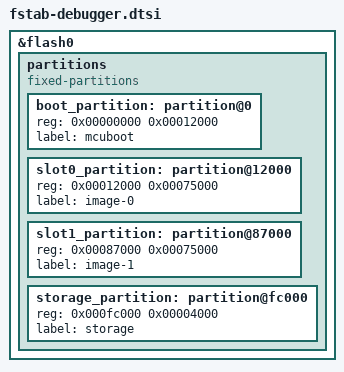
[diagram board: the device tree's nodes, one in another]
/*
 * Copyright (c) 2019 Nordic Semiconductor ASA
 *
 * SPDX-License-Identifier: Apache-2.0
 */

/* Flash partition table without support for Nordic nRF5 bootloader */

&flash0 {
	partitions {
		compatible = "fixed-partitions";
		#address-cells = <1>;
		#size-cells = <1>;

		/* The size of this partition ensures that MCUBoot can be built
		 * with an RTT console, CDC ACM support, and w/o optimizations.
		 */
		boot_partition: partition@0 {
			reg = <0x00000000 0x00012000>;
			label = "mcuboot";
		};

		slot0_partition: partition@12000 {
			reg = <0x00012000 0x00075000>;
			label = "image-0";
		};

		slot1_partition: partition@87000 {
			reg = <0x00087000 0x00075000>;
			label = "image-1";
		};

		storage_partition: partition@fc000 {
			reg = <0x000fc000 0x00004000>;
			label = "storage";
		};
	};
};
